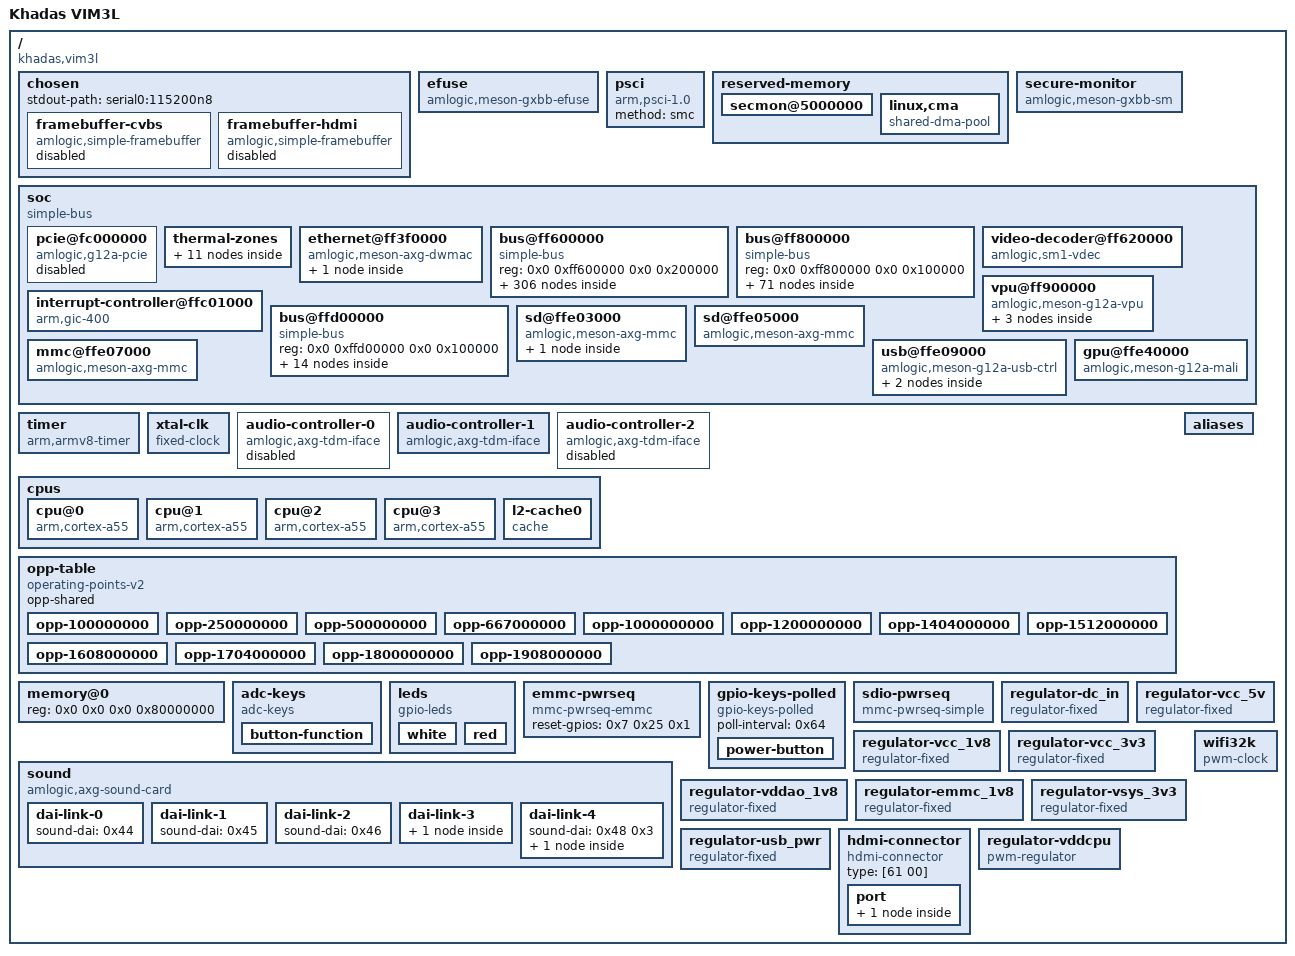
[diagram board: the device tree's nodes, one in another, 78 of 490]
/dts-v1/;

/ {
	interrupt-parent = <0x1>;
	#address-cells = <0x2>;
	#size-cells = <0x2>;
	compatible = "khadas,vim3l", "amlogic,sm1";
	model = "Khadas VIM3L";

	chosen {
		#address-cells = <0x2>;
		#size-cells = <0x2>;
		ranges;
		stdout-path = "serial0:115200n8";

		framebuffer-cvbs {
			compatible = "amlogic,simple-framebuffer", "simple-framebuffer";
			amlogic,pipeline = "vpu-cvbs";
			clocks = <0x2 0xa8 0x2 0x35 0x2 0x3a>;
			status = "disabled";
			power-domains = <0x3 0x0>;
		};

		framebuffer-hdmi {
			compatible = "amlogic,simple-framebuffer", "simple-framebuffer";
			amlogic,pipeline = "vpu-hdmi";
			clocks = <0x2 0xa8 0x2 0x35 0x2 0x3a>;
			status = "disabled";
			power-domains = <0x3 0x0>;
		};
	};

	efuse {
		compatible = "amlogic,meson-gxbb-efuse";
		clocks = <0x2 0x6a>;
		#address-cells = <0x1>;
		#size-cells = <0x1>;
		read-only;
		secure-monitor = <0x4>;
	};

	psci {
		compatible = "arm,psci-1.0";
		method = "smc";
	};

	reserved-memory {
		#address-cells = <0x2>;
		#size-cells = <0x2>;
		ranges;

		secmon@5000000 {
			reg = <0x0 0x5000000 0x0 0x300000>;
			no-map;
		};

		linux,cma {
			compatible = "shared-dma-pool";
			reusable;
			size = <0x0 0x38000000>;
			alignment = <0x0 0x400000>;
			linux,cma-default;
		};
	};

	secure-monitor {
		compatible = "amlogic,meson-gxbb-sm";
		phandle = <0x4>;
	};

	soc {
		compatible = "simple-bus";
		#address-cells = <0x2>;
		#size-cells = <0x2>;
		ranges;

		pcie@fc000000 {
			compatible = "amlogic,g12a-pcie", "snps,dw-pcie";
			reg = <0x0 0xfc000000 0x0 0x400000 0x0 0xff648000 0x0 0x2000 0x0 0xfc400000 0x0 0x200000>;
			reg-names = "elbi", "cfg", "config";
			interrupts = <0x0 0xdd 0x4>;
			#interrupt-cells = <0x1>;
			interrupt-map-mask = <0x0 0x0 0x0 0x0>;
			interrupt-map = <0x0 0x0 0x0 0x0 0x1 0x0 0xdf 0x4>;
			bus-range = <0x0 0xff>;
			#address-cells = <0x3>;
			#size-cells = <0x2>;
			device_type = "pci";
			ranges = <0x81000000 0x0 0x0 0x0 0xfc600000 0x0 0x100000 0x82000000 0x0 0xfc700000 0x0 0xfc700000 0x0 0x1900000>;
			clocks = <0x2 0x30 0x2 0x2d 0x2 0xc9>;
			clock-names = "general", "pclk", "port";
			resets = <0x5 0xc 0x5 0xf>;
			reset-names = "port", "apb";
			num-lanes = <0x1>;
			phys = <0x6 0x2>;
			phy-names = "pcie";
			status = "disabled";
			power-domains = <0x3 0x3>;
			reset-gpios = <0x7 0x39 0x1>;
		};

		thermal-zones {

			cpu-thermal {
				polling-delay = <0x3e8>;
				polling-delay-passive = <0x64>;
				thermal-sensors = <0x8>;

				trips {

					cpu-passive {
						temperature = <0x14c08>;
						hysteresis = <0x7d0>;
						type = "passive";
					};

					cpu-hot {
						temperature = <0x17318>;
						hysteresis = <0x7d0>;
						type = "hot";
					};

					cpu-critical {
						temperature = <0x1adb0>;
						hysteresis = <0x7d0>;
						type = "critical";
					};
				};
			};

			ddr-thermal {
				polling-delay = <0x3e8>;
				polling-delay-passive = <0x64>;
				thermal-sensors = <0x9>;

				trips {

					ddr-passive {
						temperature = <0x14c08>;
						hysteresis = <0x7d0>;
						type = "passive";
						phandle = <0xa>;
					};

					ddr-critical {
						temperature = <0x1adb0>;
						hysteresis = <0x7d0>;
						type = "critical";
					};
				};

				cooling-maps {

					map {
						trip = <0xa>;
						cooling-device = <0xb 0xffffffff 0xffffffff>;
					};
				};
			};
		};

		ethernet@ff3f0000 {
			compatible = "amlogic,meson-axg-dwmac", "snps,dwmac-3.70a", "snps,dwmac";
			reg = <0x0 0xff3f0000 0x0 0x10000 0x0 0xff634540 0x0 0x8>;
			interrupts = <0x0 0x8 0x4>;
			interrupt-names = "macirq";
			clocks = <0x2 0x26 0x2 0x2 0x2 0xd>;
			clock-names = "stmmaceth", "clkin0", "clkin1";
			rx-fifo-depth = <0x1000>;
			tx-fifo-depth = <0x800>;
			status = "okay";
			power-domains = <0x3 0x6>;
			pinctrl-0 = <0xc 0xd>;
			pinctrl-names = "default";
			phy-mode = "rgmii";
			phy-handle = <0xe>;
			amlogic,tx-delay-ns = <0x2>;

			mdio {
				#address-cells = <0x1>;
				#size-cells = <0x0>;
				compatible = "snps,dwmac-mdio";
				phandle = <0x1a>;
			};
		};

		bus@ff600000 {
			compatible = "simple-bus";
			reg = <0x0 0xff600000 0x0 0x200000>;
			#address-cells = <0x2>;
			#size-cells = <0x2>;
			ranges = <0x0 0x0 0x0 0xff600000 0x0 0x200000>;

			hdmi-tx@0 {
				compatible = "amlogic,meson-g12a-dw-hdmi";
				reg = <0x0 0x0 0x0 0x10000>;
				interrupts = <0x0 0x39 0x1>;
				resets = <0x5 0x13 0x5 0x42 0x5 0x4f>;
				reset-names = "hdmitx_apb", "hdmitx", "hdmitx_phy";
				clocks = <0x2 0xa8 0x2 0x35 0x2 0x3a>;
				clock-names = "isfr", "iahb", "venci";
				#address-cells = <0x1>;
				#size-cells = <0x0>;
				#sound-dai-cells = <0x0>;
				status = "okay";
				pinctrl-0 = <0xf 0x10>;
				pinctrl-names = "default";
				hdmi-supply = <0x11>;
				phandle = <0x21>;

				port@0 {
					reg = <0x0>;

					endpoint {
						remote-endpoint = <0x12>;
						phandle = <0x2b>;
					};
				};

				port@1 {
					reg = <0x1>;

					endpoint {
						remote-endpoint = <0x13>;
						phandle = <0x49>;
					};
				};
			};

			bus@30000 {
				compatible = "simple-bus";
				reg = <0x0 0x30000 0x0 0x2000>;
				#address-cells = <0x2>;
				#size-cells = <0x2>;
				ranges = <0x0 0x0 0x0 0x30000 0x0 0x2000>;

				rng@218 {
					compatible = "amlogic,meson-rng";
					reg = <0x0 0x218 0x0 0x4>;
				};
			};

			audio-controller@32000 {
				compatible = "amlogic,t9015";
				reg = <0x0 0x32000 0x0 0x14>;
				#sound-dai-cells = <0x0>;
				sound-name-prefix = "ACODEC";
				clocks = <0x2 0x24>;
				clock-names = "pclk";
				resets = <0x5 0x3d>;
				status = "disabled";
			};

			bus@34400 {
				compatible = "simple-bus";
				reg = <0x0 0x34400 0x0 0x400>;
				#address-cells = <0x2>;
				#size-cells = <0x2>;
				ranges = <0x0 0x0 0x0 0x34400 0x0 0x400>;

				pinctrl@40 {
					compatible = "amlogic,meson-g12a-periphs-pinctrl";
					#address-cells = <0x2>;
					#size-cells = <0x2>;
					ranges;
					phandle = <0x14>;

					bank@40 {
						reg = <0x0 0x40 0x0 0x4c 0x0 0xe8 0x0 0x18 0x0 0x120 0x0 0x18 0x0 0x2c0 0x0 0x40 0x0 0x340 0x0 0x1c>;
						reg-names = "gpio", "pull", "pull-enable", "mux", "ds";
						gpio-controller;
						#gpio-cells = <0x2>;
						gpio-ranges = <0x14 0x0 0x0 0x56>;
						phandle = <0x7>;
					};

					cec_ao_a_h {
						phandle = <0x20>;

						mux {
							groups = "cec_ao_a_h";
							function = "cec_ao_a_h";
							bias-disable;
						};
					};

					cec_ao_b_h {
						phandle = <0x22>;

						mux {
							groups = "cec_ao_b_h";
							function = "cec_ao_b_h";
							bias-disable;
						};
					};

					emmc {
						phandle = <0x36>;

						mux-0 {
							groups = "emmc_nand_d0", "emmc_nand_d1", "emmc_nand_d2", "emmc_nand_d3", "emmc_nand_d4", "emmc_nand_d5", "emmc_nand_d6", "emmc_nand_d7", "emmc_cmd";
							function = "emmc";
							bias-pull-up;
							drive-strength-microamp = <0xfa0>;
						};

						mux-1 {
							groups = "emmc_clk";
							function = "emmc";
							bias-disable;
							drive-strength-microamp = <0xfa0>;
						};
					};

					emmc-ds {
						phandle = <0x37>;

						mux {
							groups = "emmc_nand_ds";
							function = "emmc";
							bias-pull-down;
							drive-strength-microamp = <0xfa0>;
						};
					};

					emmc_clk_gate {
						phandle = <0x38>;

						mux {
							groups = "BOOT_8";
							function = "gpio_periphs";
							bias-pull-down;
							drive-strength-microamp = <0xfa0>;
						};
					};

					hdmitx_ddc {
						phandle = <0x10>;

						mux {
							groups = "hdmitx_sda", "hdmitx_sck";
							function = "hdmitx";
							bias-disable;
							drive-strength-microamp = <0xfa0>;
						};
					};

					hdmitx_hpd {
						phandle = <0xf>;

						mux {
							groups = "hdmitx_hpd_in";
							function = "hdmitx";
							bias-disable;
						};
					};

					i2c0-sda-c {

						mux {
							groups = "i2c0_sda_c";
							function = "i2c0";
							bias-disable;
							drive-strength-microamp = <0xbb8>;
						};
					};

					i2c0-sck-c {

						mux {
							groups = "i2c0_sck_c";
							function = "i2c0";
							bias-disable;
							drive-strength-microamp = <0xbb8>;
						};
					};

					i2c0-sda-z0 {

						mux {
							groups = "i2c0_sda_z0";
							function = "i2c0";
							bias-disable;
							drive-strength-microamp = <0xbb8>;
						};
					};

					i2c0-sck-z1 {

						mux {
							groups = "i2c0_sck_z1";
							function = "i2c0";
							bias-disable;
							drive-strength-microamp = <0xbb8>;
						};
					};

					i2c0-sda-z7 {

						mux {
							groups = "i2c0_sda_z7";
							function = "i2c0";
							bias-disable;
							drive-strength-microamp = <0xbb8>;
						};
					};

					i2c0-sda-z8 {

						mux {
							groups = "i2c0_sda_z8";
							function = "i2c0";
							bias-disable;
							drive-strength-microamp = <0xbb8>;
						};
					};

					i2c1-sda-x {

						mux {
							groups = "i2c1_sda_x";
							function = "i2c1";
							bias-disable;
							drive-strength-microamp = <0xbb8>;
						};
					};

					i2c1-sck-x {

						mux {
							groups = "i2c1_sck_x";
							function = "i2c1";
							bias-disable;
							drive-strength-microamp = <0xbb8>;
						};
					};

					i2c1-sda-h2 {

						mux {
							groups = "i2c1_sda_h2";
							function = "i2c1";
							bias-disable;
							drive-strength-microamp = <0xbb8>;
						};
					};

					i2c1-sck-h3 {

						mux {
							groups = "i2c1_sck_h3";
							function = "i2c1";
							bias-disable;
							drive-strength-microamp = <0xbb8>;
						};
					};

					i2c1-sda-h6 {

						mux {
							groups = "i2c1_sda_h6";
							function = "i2c1";
							bias-disable;
							drive-strength-microamp = <0xbb8>;
						};
					};

					i2c1-sck-h7 {

						mux {
							groups = "i2c1_sck_h7";
							function = "i2c1";
							bias-disable;
							drive-strength-microamp = <0xbb8>;
						};
					};

					i2c2-sda-x {

						mux {
							groups = "i2c2_sda_x";
							function = "i2c2";
							bias-disable;
							drive-strength-microamp = <0xbb8>;
						};
					};

					i2c2-sck-x {

						mux {
							groups = "i2c2_sck_x";
							function = "i2c2";
							bias-disable;
							drive-strength-microamp = <0xbb8>;
						};
					};

					i2c2-sda-z {

						mux {
							groups = "i2c2_sda_z";
							function = "i2c2";
							bias-disable;
							drive-strength-microamp = <0xbb8>;
						};
					};

					i2c2-sck-z {

						mux {
							groups = "i2c2_sck_z";
							function = "i2c2";
							bias-disable;
							drive-strength-microamp = <0xbb8>;
						};
					};

					i2c3-sda-h {

						mux {
							groups = "i2c3_sda_h";
							function = "i2c3";
							bias-disable;
							drive-strength-microamp = <0xbb8>;
						};
					};

					i2c3-sck-h {

						mux {
							groups = "i2c3_sck_h";
							function = "i2c3";
							bias-disable;
							drive-strength-microamp = <0xbb8>;
						};
					};

					i2c3-sda-a {

						mux {
							groups = "i2c3_sda_a";
							function = "i2c3";
							bias-disable;
							drive-strength-microamp = <0xbb8>;
						};
					};

					i2c3-sck-a {

						mux {
							groups = "i2c3_sck_a";
							function = "i2c3";
							bias-disable;
							drive-strength-microamp = <0xbb8>;
						};
					};

					mclk0-a {

						mux {
							groups = "mclk0_a";
							function = "mclk0";
							bias-disable;
							drive-strength-microamp = <0xbb8>;
						};
					};

					mclk1-a {

						mux {
							groups = "mclk1_a";
							function = "mclk1";
							bias-disable;
							drive-strength-microamp = <0xbb8>;
						};
					};

					mclk1-x {

						mux {
							groups = "mclk1_x";
							function = "mclk1";
							bias-disable;
							drive-strength-microamp = <0xbb8>;
						};
					};

					mclk1-z {

						mux {
							groups = "mclk1_z";
							function = "mclk1";
							bias-disable;
							drive-strength-microamp = <0xbb8>;
						};
					};

					pdm-din0-a {

						mux {
							groups = "pdm_din0_a";
							function = "pdm";
							bias-disable;
						};
					};

					pdm-din0-c {

						mux {
							groups = "pdm_din0_c";
							function = "pdm";
							bias-disable;
						};
					};

					pdm-din0-x {

						mux {
							groups = "pdm_din0_x";
							function = "pdm";
							bias-disable;
						};
					};

					pdm-din0-z {

						mux {
							groups = "pdm_din0_z";
							function = "pdm";
							bias-disable;
						};
					};

					pdm-din1-a {

						mux {
							groups = "pdm_din1_a";
							function = "pdm";
							bias-disable;
						};
					};

					pdm-din1-c {

						mux {
							groups = "pdm_din1_c";
							function = "pdm";
							bias-disable;
						};
					};

					pdm-din1-x {

						mux {
							groups = "pdm_din1_x";
							function = "pdm";
							bias-disable;
						};
					};

					pdm-din1-z {

						mux {
							groups = "pdm_din1_z";
							function = "pdm";
							bias-disable;
						};
					};

					pdm-din2-a {

						mux {
							groups = "pdm_din2_a";
							function = "pdm";
							bias-disable;
						};
					};

					pdm-din2-c {

						mux {
							groups = "pdm_din2_c";
							function = "pdm";
							bias-disable;
						};
					};

					pdm-din2-x {

						mux {
							groups = "pdm_din2_x";
							function = "pdm";
							bias-disable;
						};
					};

					pdm-din2-z {

						mux {
							groups = "pdm_din2_z";
							function = "pdm";
							bias-disable;
						};
					};

					pdm-din3-a {

						mux {
							groups = "pdm_din3_a";
							function = "pdm";
							bias-disable;
						};
					};

					pdm-din3-c {

						mux {
							groups = "pdm_din3_c";
							function = "pdm";
							bias-disable;
						};
					};

					pdm-din3-x {

						mux {
							groups = "pdm_din3_x";
							function = "pdm";
							bias-disable;
						};
					};

					pdm-din3-z {

						mux {
							groups = "pdm_din3_z";
							function = "pdm";
							bias-disable;
						};
					};

					pdm-dclk-a {

						mux {
							groups = "pdm_dclk_a";
							function = "pdm";
							bias-disable;
							drive-strength-microamp = <0x1f4>;
						};
					};

					pdm-dclk-c {

						mux {
							groups = "pdm_dclk_c";
							function = "pdm";
							bias-disable;
							drive-strength-microamp = <0x1f4>;
						};
					};

					pdm-dclk-x {

						mux {
							groups = "pdm_dclk_x";
							function = "pdm";
							bias-disable;
							drive-strength-microamp = <0x1f4>;
						};
					};

					pdm-dclk-z {

						mux {
							groups = "pdm_dclk_z";
							function = "pdm";
							bias-disable;
							drive-strength-microamp = <0x1f4>;
						};
					};

					pwm-a {

						mux {
							groups = "pwm_a";
							function = "pwm_a";
							bias-disable;
						};
					};

					pwm-b-x7 {

						mux {
							groups = "pwm_b_x7";
							function = "pwm_b";
							bias-disable;
						};
					};

					pwm-b-x19 {

						mux {
							groups = "pwm_b_x19";
							function = "pwm_b";
							bias-disable;
						};
					};

					pwm-c-c {

						mux {
							groups = "pwm_c_c";
							function = "pwm_c";
							bias-disable;
						};
					};

					pwm-c-x5 {

						mux {
							groups = "pwm_c_x5";
							function = "pwm_c";
							bias-disable;
						};
					};

					pwm-c-x8 {

						mux {
							groups = "pwm_c_x8";
							function = "pwm_c";
							bias-disable;
						};
					};

					pwm-d-x3 {

						mux {
							groups = "pwm_d_x3";
							function = "pwm_d";
							bias-disable;
						};
					};

					pwm-d-x6 {

						mux {
							groups = "pwm_d_x6";
							function = "pwm_d";
							bias-disable;
						};
					};

					pwm-e {
						phandle = <0x2c>;

						mux {
							groups = "pwm_e";
							function = "pwm_e";
							bias-disable;
						};
					};

					pwm-f-x {

						mux {
							groups = "pwm_f_x";
							function = "pwm_f";
							bias-disable;
						};
					};

					pwm-f-h {

						mux {
							groups = "pwm_f_h";
							function = "pwm_f";
							bias-disable;
						};
					};

					sdcard_c {
						phandle = <0x34>;

						mux-0 {
							groups = "sdcard_d0_c", "sdcard_d1_c", "sdcard_d2_c", "sdcard_d3_c", "sdcard_cmd_c";
							function = "sdcard";
							bias-pull-up;
							drive-strength-microamp = <0xfa0>;
						};

						mux-1 {
							groups = "sdcard_clk_c";
							function = "sdcard";
							bias-disable;
							drive-strength-microamp = <0xfa0>;
						};
					};

					sdcard_clk_gate_c {
						phandle = <0x35>;

						mux {
							groups = "GPIOC_4";
							function = "gpio_periphs";
							bias-pull-down;
							drive-strength-microamp = <0xfa0>;
						};
					};

					sdcard_z {

						mux-0 {
							groups = "sdcard_d0_z", "sdcard_d1_z", "sdcard_d2_z", "sdcard_d3_z", "sdcard_cmd_z";
							function = "sdcard";
							bias-pull-up;
							drive-strength-microamp = <0xfa0>;
						};

						mux-1 {
							groups = "sdcard_clk_z";
							function = "sdcard";
							bias-disable;
							drive-strength-microamp = <0xfa0>;
						};
					};

					sdcard_clk_gate_z {

						mux {
							groups = "GPIOZ_6";
							function = "gpio_periphs";
							bias-pull-down;
							drive-strength-microamp = <0xfa0>;
						};
					};

					sdio {
						phandle = <0x30>;

						mux {
							groups = "sdio_d0", "sdio_d1", "sdio_d2", "sdio_d3", "sdio_clk", "sdio_cmd";
							function = "sdio";
							bias-disable;
							drive-strength-microamp = <0xfa0>;
						};
					};

					sdio_clk_gate {
						phandle = <0x31>;

						mux {
							groups = "GPIOX_4";
							function = "gpio_periphs";
							bias-pull-down;
							drive-strength-microamp = <0xfa0>;
						};
					};

					spdif-in-a10 {

						mux {
							groups = "spdif_in_a10";
							function = "spdif_in";
							bias-disable;
						};
					};

					spdif-in-a12 {

						mux {
							groups = "spdif_in_a12";
							function = "spdif_in";
							bias-disable;
						};
					};

					spdif-in-h {

						mux {
							groups = "spdif_in_h";
							function = "spdif_in";
							bias-disable;
						};
					};

					spdif-out-h {

						mux {
							groups = "spdif_out_h";
							function = "spdif_out";
							drive-strength-microamp = <0x1f4>;
							bias-disable;
						};
					};

					spdif-out-a11 {

						mux {
							groups = "spdif_out_a11";
							function = "spdif_out";
							drive-strength-microamp = <0x1f4>;
							bias-disable;
						};
					};

					spdif-out-a13 {

						mux {
							groups = "spdif_out_a13";
							function = "spdif_out";
							drive-strength-microamp = <0x1f4>;
							bias-disable;
						};
					};

					tdm-a-din0 {

						mux {
							groups = "tdm_a_din0";
							function = "tdm_a";
							bias-disable;
						};
					};

					tdm-a-din1 {

						mux {
							groups = "tdm_a_din1";
							function = "tdm_a";
							bias-disable;
						};
					};

					tdm-a-dout0 {

						mux {
							groups = "tdm_a_dout0";
							function = "tdm_a";
							bias-disable;
							drive-strength-microamp = <0xbb8>;
						};
					};

					tdm-a-dout1 {

						mux {
							groups = "tdm_a_dout1";
							function = "tdm_a";
							bias-disable;
							drive-strength-microamp = <0xbb8>;
						};
					};

					tdm-a-fs {

						mux {
							groups = "tdm_a_fs";
							function = "tdm_a";
							bias-disable;
							drive-strength-microamp = <0xbb8>;
						};
					};

					tdm-a-sclk {

						mux {
							groups = "tdm_a_sclk";
							function = "tdm_a";
							bias-disable;
							drive-strength-microamp = <0xbb8>;
						};
					};

					tdm-a-slv-fs {

						mux {
							groups = "tdm_a_slv_fs";
							function = "tdm_a";
							bias-disable;
						};
					};

					tdm-a-slv-sclk {

						mux {
							groups = "tdm_a_slv_sclk";
							function = "tdm_a";
							bias-disable;
						};
					};

					tdm-b-din0 {

						mux {
							groups = "tdm_b_din0";
							function = "tdm_b";
							bias-disable;
						};
					};

					tdm-b-din1 {

						mux {
							groups = "tdm_b_din1";
							function = "tdm_b";
							bias-disable;
						};
					};

					tdm-b-din2 {

						mux {
							groups = "tdm_b_din2";
							function = "tdm_b";
							bias-disable;
						};
					};

					tdm-b-din3-a {

						mux {
							groups = "tdm_b_din3_a";
							function = "tdm_b";
							bias-disable;
						};
					};

					tdm-b-din3-h {

						mux {
							groups = "tdm_b_din3_h";
							function = "tdm_b";
							bias-disable;
						};
					};

					tdm-b-dout0 {

						mux {
							groups = "tdm_b_dout0";
							function = "tdm_b";
							bias-disable;
							drive-strength-microamp = <0xbb8>;
						};
					};

					tdm-b-dout1 {

						mux {
							groups = "tdm_b_dout1";
							function = "tdm_b";
							bias-disable;
							drive-strength-microamp = <0xbb8>;
						};
					};

					tdm-b-dout2 {

						mux {
							groups = "tdm_b_dout2";
							function = "tdm_b";
							bias-disable;
							drive-strength-microamp = <0xbb8>;
						};
					};

					tdm-b-dout3-a {

						mux {
							groups = "tdm_b_dout3_a";
							function = "tdm_b";
							bias-disable;
							drive-strength-microamp = <0xbb8>;
						};
					};

					tdm-b-dout3-h {

						mux {
							groups = "tdm_b_dout3_h";
							function = "tdm_b";
							bias-disable;
							drive-strength-microamp = <0xbb8>;
						};
					};

					tdm-b-fs {

						mux {
							groups = "tdm_b_fs";
							function = "tdm_b";
							bias-disable;
							drive-strength-microamp = <0xbb8>;
						};
					};

					tdm-b-sclk {

						mux {
							groups = "tdm_b_sclk";
							function = "tdm_b";
							bias-disable;
							drive-strength-microamp = <0xbb8>;
						};
					};

					tdm-b-slv-fs {

						mux {
							groups = "tdm_b_slv_fs";
							function = "tdm_b";
							bias-disable;
						};
					};

					tdm-b-slv-sclk {

						mux {
							groups = "tdm_b_slv_sclk";
							function = "tdm_b";
							bias-disable;
						};
					};

					tdm-c-din0-a {

						mux {
							groups = "tdm_c_din0_a";
							function = "tdm_c";
							bias-disable;
						};
					};

					tdm-c-din0-z {

						mux {
							groups = "tdm_c_din0_z";
							function = "tdm_c";
							bias-disable;
						};
					};

					tdm-c-din1-a {

						mux {
							groups = "tdm_c_din1_a";
							function = "tdm_c";
							bias-disable;
						};
					};

					tdm-c-din1-z {

						mux {
							groups = "tdm_c_din1_z";
							function = "tdm_c";
							bias-disable;
						};
					};

					tdm-c-din2-a {

						mux {
							groups = "tdm_c_din2_a";
							function = "tdm_c";
							bias-disable;
						};
					};

					eth-leds {

						mux {
							groups = "eth_link_led", "eth_act_led";
							function = "eth";
							bias-disable;
						};
					};

					eth {
						phandle = <0xc>;

						mux {
							groups = "eth_mdio", "eth_mdc", "eth_rgmii_rx_clk", "eth_rx_dv", "eth_rxd0", "eth_rxd1", "eth_txen", "eth_txd0", "eth_txd1";
							function = "eth";
							drive-strength-microamp = <0xfa0>;
							bias-disable;
						};
					};

					eth-rgmii {
						phandle = <0xd>;

						mux {
							groups = "eth_rxd2_rgmii", "eth_rxd3_rgmii", "eth_rgmii_tx_clk", "eth_txd2_rgmii", "eth_txd3_rgmii";
							function = "eth";
							drive-strength-microamp = <0xfa0>;
							bias-disable;
						};
					};

					tdm-c-din2-z {

						mux {
							groups = "tdm_c_din2_z";
							function = "tdm_c";
							bias-disable;
						};
					};

					tdm-c-din3-a {

						mux {
							groups = "tdm_c_din3_a";
							function = "tdm_c";
							bias-disable;
						};
					};

					tdm-c-din3-z {

						mux {
							groups = "tdm_c_din3_z";
							function = "tdm_c";
							bias-disable;
						};
					};

					tdm-c-dout0-a {

						mux {
							groups = "tdm_c_dout0_a";
							function = "tdm_c";
							bias-disable;
							drive-strength-microamp = <0xbb8>;
						};
					};

					tdm-c-dout0-z {

						mux {
							groups = "tdm_c_dout0_z";
							function = "tdm_c";
							bias-disable;
							drive-strength-microamp = <0xbb8>;
						};
					};

					tdm-c-dout1-a {

						mux {
							groups = "tdm_c_dout1_a";
							function = "tdm_c";
							bias-disable;
							drive-strength-microamp = <0xbb8>;
						};
					};

					tdm-c-dout1-z {

						mux {
							groups = "tdm_c_dout1_z";
							function = "tdm_c";
							bias-disable;
							drive-strength-microamp = <0xbb8>;
						};
					};

					tdm-c-dout2-a {

						mux {
							groups = "tdm_c_dout2_a";
							function = "tdm_c";
							bias-disable;
							drive-strength-microamp = <0xbb8>;
						};
					};

					tdm-c-dout2-z {

						mux {
							groups = "tdm_c_dout2_z";
							function = "tdm_c";
							bias-disable;
							drive-strength-microamp = <0xbb8>;
						};
					};

					tdm-c-dout3-a {

						mux {
							groups = "tdm_c_dout3_a";
							function = "tdm_c";
							bias-disable;
							drive-strength-microamp = <0xbb8>;
						};
					};

					tdm-c-dout3-z {

						mux {
							groups = "tdm_c_dout3_z";
							function = "tdm_c";
							bias-disable;
							drive-strength-microamp = <0xbb8>;
						};
					};

					tdm-c-fs-a {

						mux {
							groups = "tdm_c_fs_a";
							function = "tdm_c";
							bias-disable;
							drive-strength-microamp = <0xbb8>;
						};
					};

					tdm-c-fs-z {

						mux {
							groups = "tdm_c_fs_z";
							function = "tdm_c";
							bias-disable;
							drive-strength-microamp = <0xbb8>;
						};
					};

					tdm-c-sclk-a {

						mux {
							groups = "tdm_c_sclk_a";
							function = "tdm_c";
							bias-disable;
							drive-strength-microamp = <0xbb8>;
						};
					};

					tdm-c-sclk-z {

						mux {
							groups = "tdm_c_sclk_z";
							function = "tdm_c";
							bias-disable;
							drive-strength-microamp = <0xbb8>;
						};
					};

					tdm-c-slv-fs-a {

						mux {
							groups = "tdm_c_slv_fs_a";
							function = "tdm_c";
							bias-disable;
						};
					};

					tdm-c-slv-fs-z {

						mux {
							groups = "tdm_c_slv_fs_z";
							function = "tdm_c";
							bias-disable;
						};
					};

					tdm-c-slv-sclk-a {

						mux {
							groups = "tdm_c_slv_sclk_a";
							function = "tdm_c";
							bias-disable;
						};
					};

					tdm-c-slv-sclk-z {

						mux {
							groups = "tdm_c_slv_sclk_z";
							function = "tdm_c";
							bias-disable;
						};
					};

					uart-a {
						phandle = <0x2d>;

						mux {
							groups = "uart_a_tx", "uart_a_rx";
							function = "uart_a";
							bias-disable;
						};
					};

					uart-a-cts-rts {
						phandle = <0x2e>;

						mux {
							groups = "uart_a_cts", "uart_a_rts";
							function = "uart_a";
							bias-disable;
						};
					};

					uart-b {

						mux {
							groups = "uart_b_tx", "uart_b_rx";
							function = "uart_b";
							bias-disable;
						};
					};

					uart-c {

						mux {
							groups = "uart_c_tx", "uart_c_rx";
							function = "uart_c";
							bias-disable;
						};
					};

					uart-c-cts-rts {

						mux {
							groups = "uart_c_cts", "uart_c_rts";
							function = "uart_c";
							bias-disable;
						};
					};
				};
			};

			temperature-sensor@34800 {
				compatible = "amlogic,g12a-cpu-thermal", "amlogic,g12a-thermal";
				reg = <0x0 0x34800 0x0 0x50>;
				interrupts = <0x0 0x23 0x1>;
				clocks = <0x2 0xd4>;
				#thermal-sensor-cells = <0x0>;
				amlogic,ao-secure = <0x15>;
				phandle = <0x8>;
			};

			temperature-sensor@34c00 {
				compatible = "amlogic,g12a-ddr-thermal", "amlogic,g12a-thermal";
				reg = <0x0 0x34c00 0x0 0x50>;
				interrupts = <0x0 0x24 0x1>;
				clocks = <0x2 0xd4>;
				#thermal-sensor-cells = <0x0>;
				amlogic,ao-secure = <0x15>;
				phandle = <0x9>;
			};

			phy@36000 {
				compatible = "amlogic,g12a-usb2-phy";
				reg = <0x0 0x36000 0x0 0x2000>;
				clocks = <0x16>;
				clock-names = "xtal";
				resets = <0x5 0x30>;
				reset-names = "phy";
				#phy-cells = <0x0>;
				phy-supply = <0x17>;
				phandle = <0x3b>;
			};

			bus@38000 {
				compatible = "simple-bus";
				reg = <0x0 0x38000 0x0 0x400>;
				#address-cells = <0x2>;
				#size-cells = <0x2>;
				ranges = <0x0 0x0 0x0 0x38000 0x0 0x400>;

				video-lut@48 {
					compatible = "amlogic,canvas";
					reg = <0x0 0x48 0x0 0x14>;
					phandle = <0x2a>;
				};
			};

			phy@3a000 {
				compatible = "amlogic,g12a-usb2-phy";
				reg = <0x0 0x3a000 0x0 0x2000>;
				clocks = <0x16>;
				clock-names = "xtal";
				resets = <0x5 0x31>;
				reset-names = "phy";
				#phy-cells = <0x0>;
				phy-supply = <0x18>;
				phandle = <0x3c>;
			};

			bus@3c000 {
				compatible = "simple-bus";
				reg = <0x0 0x3c000 0x0 0x1400>;
				#address-cells = <0x2>;
				#size-cells = <0x2>;
				ranges = <0x0 0x0 0x0 0x3c000 0x0 0x1400>;

				system-controller@0 {
					compatible = "amlogic,meson-gx-hhi-sysctrl", "simple-mfd", "syscon";
					reg = <0x0 0x0 0x0 0x400>;

					clock-controller {
						compatible = "amlogic,sm1-clkc";
						#clock-cells = <0x1>;
						clocks = <0x16>;
						clock-names = "xtal";
						phandle = <0x2>;
					};

					power-controller {
						compatible = "amlogic,meson-sm1-pwrc";
						#power-domain-cells = <0x1>;
						amlogic,ao-sysctrl = <0x19>;
						resets = <0x5 0x5 0x5 0xa 0x5 0xd 0x5 0x25 0x5 0x85 0x5 0x86 0x5 0x87 0x5 0x89 0x5 0x8c 0x5 0x8d 0x5 0xe7>;
						reset-names = "viu", "venc", "vcbus", "bt656", "rdma", "venci", "vencp", "vdac", "vdi6", "vencl", "vid_lock";
						clocks = <0x2 0x74 0x2 0x7c>;
						clock-names = "vpu", "vapb";
						assigned-clocks = <0x2 0x6e 0x2 0x70 0x2 0x74 0x2 0x75 0x2 0x77 0x2 0x7b>;
						assigned-clock-parents = <0x2 0x3 0x0 0x2 0x70 0x2 0x4 0x0 0x2 0x77>;
						assigned-clock-rates = <0x0 0x27bc86aa 0x0 0x0 0xee6b280 0x0>;
						phandle = <0x3>;
					};
				};
			};

			phy@46000 {
				compatible = "amlogic,g12a-usb3-pcie-phy";
				reg = <0x0 0x46000 0x0 0x2000>;
				clocks = <0x2 0xc9>;
				clock-names = "ref_clk";
				resets = <0x5 0xe>;
				reset-names = "phy";
				assigned-clocks = <0x2 0xc9>;
				assigned-clock-rates = <0x5f5e100>;
				#phy-cells = <0x1>;
				phy-supply = <0x18>;
				phandle = <0x6>;
			};

			mdio-multiplexer@4c000 {
				compatible = "amlogic,g12a-mdio-mux";
				reg = <0x0 0x4c000 0x0 0xa4>;
				clocks = <0x2 0x13 0x16 0x2 0xb1>;
				clock-names = "pclk", "clkin0", "clkin1";
				mdio-parent-bus = <0x1a>;
				#address-cells = <0x1>;
				#size-cells = <0x0>;

				mdio@0 {
					reg = <0x0>;
					#address-cells = <0x1>;
					#size-cells = <0x0>;

					ethernet-phy@0 {
						reg = <0x0>;
						max-speed = <0x3e8>;
						interrupt-parent = <0x1b>;
						interrupts = <0x1a 0x8>;
						phandle = <0xe>;
					};
				};

				mdio@1 {
					reg = <0x1>;
					#address-cells = <0x1>;
					#size-cells = <0x0>;

					ethernet_phy@8 {
						compatible = "ethernet-phy-id0180.3301", "ethernet-phy-ieee802.3-c22";
						interrupts = <0x0 0x9 0x4>;
						reg = <0x8>;
						max-speed = <0x64>;
					};
				};
			};

			bus@60000 {
				compatible = "simple-bus";
				reg = <0x0 0x60000 0x0 0x1000>;
				#address-cells = <0x2>;
				#size-cells = <0x2>;
				ranges = <0x0 0x0 0x0 0x60000 0x0 0x1000>;

				clock-controller@0 {
					status = "okay";
					compatible = "amlogic,sm1-audio-clkc";
					reg = <0x0 0x0 0x0 0xb4>;
					#clock-cells = <0x1>;
					#reset-cells = <0x1>;
					clocks = <0x2 0x25 0x2 0xb 0x2 0xc 0x2 0xd 0x2 0xe 0x2 0x4a 0x2 0x3 0x2 0x4 0x2 0x5>;
					clock-names = "pclk", "mst_in0", "mst_in1", "mst_in2", "mst_in3", "mst_in4", "mst_in5", "mst_in6", "mst_in7";
					resets = <0x5 0x41>;
					phandle = <0x1c>;
				};

				audio-controller@100 {
					compatible = "amlogic,sm1-toddr", "amlogic,axg-toddr";
					reg = <0x0 0x100 0x0 0x2c>;
					#sound-dai-cells = <0x0>;
					sound-name-prefix = "TODDR_A";
					interrupts = <0x0 0x94 0x1>;
					clocks = <0x1c 0x29>;
					resets = <0x1d 0x0 0x1c 0x6>;
					reset-names = "arb", "rst";
					amlogic,fifo-depth = <0x2000>;
					status = "disabled";
				};

				audio-controller@140 {
					compatible = "amlogic,sm1-toddr", "amlogic,axg-toddr";
					reg = <0x0 0x140 0x0 0x2c>;
					#sound-dai-cells = <0x0>;
					sound-name-prefix = "TODDR_B";
					interrupts = <0x0 0x95 0x1>;
					clocks = <0x1c 0x2a>;
					resets = <0x1d 0x1 0x1c 0x7>;
					reset-names = "arb", "rst";
					amlogic,fifo-depth = <0x100>;
					status = "disabled";
				};

				audio-controller@180 {
					compatible = "amlogic,sm1-toddr", "amlogic,axg-toddr";
					reg = <0x0 0x180 0x0 0x2c>;
					#sound-dai-cells = <0x0>;
					sound-name-prefix = "TODDR_C";
					interrupts = <0x0 0x96 0x1>;
					clocks = <0x1c 0x2b>;
					resets = <0x1d 0x2 0x1c 0x8>;
					reset-names = "arb", "rst";
					amlogic,fifo-depth = <0x100>;
					status = "disabled";
				};

				audio-controller@1c0 {
					compatible = "amlogic,sm1-frddr", "amlogic,axg-frddr";
					reg = <0x0 0x1c0 0x0 0x2c>;
					#sound-dai-cells = <0x0>;
					sound-name-prefix = "FRDDR_A";
					interrupts = <0x0 0x98 0x1>;
					clocks = <0x1c 0x26>;
					resets = <0x1d 0x3 0x1c 0x9>;
					reset-names = "arb", "rst";
					amlogic,fifo-depth = <0x200>;
					status = "okay";
					phandle = <0x44>;
				};

				audio-controller@200 {
					compatible = "amlogic,sm1-frddr", "amlogic,axg-frddr";
					reg = <0x0 0x200 0x0 0x2c>;
					#sound-dai-cells = <0x0>;
					sound-name-prefix = "FRDDR_B";
					interrupts = <0x0 0x99 0x1>;
					clocks = <0x1c 0x27>;
					resets = <0x1d 0x4 0x1c 0xa>;
					reset-names = "arb", "rst";
					amlogic,fifo-depth = <0x100>;
					status = "okay";
					phandle = <0x45>;
				};

				audio-controller@240 {
					compatible = "amlogic,sm1-frddr", "amlogic,axg-frddr";
					reg = <0x0 0x240 0x0 0x2c>;
					#sound-dai-cells = <0x0>;
					sound-name-prefix = "FRDDR_C";
					interrupts = <0x0 0x9a 0x1>;
					clocks = <0x1c 0x28>;
					resets = <0x1d 0x5 0x1c 0xb>;
					reset-names = "arb", "rst";
					amlogic,fifo-depth = <0x100>;
					status = "okay";
					phandle = <0x46>;
				};

				reset-controller@280 {
					status = "okay";
					compatible = "amlogic,meson-sm1-audio-arb";
					reg = <0x0 0x280 0x0 0x4>;
					#reset-cells = <0x1>;
					clocks = <0x1c 0x1d>;
					phandle = <0x1d>;
				};

				audio-controller@300 {
					compatible = "amlogic,sm1-tdmin", "amlogic,axg-tdmin";
					reg = <0x0 0x300 0x0 0x40>;
					sound-name-prefix = "TDMIN_A";
					resets = <0x1c 0x1>;
					clocks = <0x1c 0x1f 0x1c 0x7b 0x1c 0x74 0x1c 0x82 0x1c 0x82>;
					clock-names = "pclk", "sclk", "sclk_sel", "lrclk", "lrclk_sel";
					status = "disabled";
				};

				audio-controller@340 {
					compatible = "amlogic,sm1-tdmin", "amlogic,axg-tdmin";
					reg = <0x0 0x340 0x0 0x40>;
					sound-name-prefix = "TDMIN_B";
					resets = <0x1c 0x2>;
					clocks = <0x1c 0x20 0x1c 0x7c 0x1c 0x75 0x1c 0x83 0x1c 0x83>;
					clock-names = "pclk", "sclk", "sclk_sel", "lrclk", "lrclk_sel";
					status = "disabled";
				};

				audio-controller@380 {
					compatible = "amlogic,sm1-tdmin", "amlogic,axg-tdmin";
					reg = <0x0 0x380 0x0 0x40>;
					sound-name-prefix = "TDMIN_C";
					resets = <0x1c 0x3>;
					clocks = <0x1c 0x21 0x1c 0x7d 0x1c 0x76 0x1c 0x84 0x1c 0x84>;
					clock-names = "pclk", "sclk", "sclk_sel", "lrclk", "lrclk_sel";
					status = "disabled";
				};

				audio-controller@3c0 {
					compatible = "amlogic,sm1-tdmin", "amlogic,axg-tdmin";
					reg = <0x0 0x3c0 0x0 0x40>;
					sound-name-prefix = "TDMIN_LB";
					resets = <0x1c 0x4>;
					clocks = <0x1c 0x22 0x1c 0x7e 0x1c 0x77 0x1c 0x85 0x1c 0x85>;
					clock-names = "pclk", "sclk", "sclk_sel", "lrclk", "lrclk_sel";
					status = "disabled";
				};

				audio-controller@500 {
					compatible = "amlogic,sm1-tdmout";
					reg = <0x0 0x500 0x0 0x40>;
					sound-name-prefix = "TDMOUT_A";
					resets = <0x1c 0xc>;
					clocks = <0x1c 0x23 0x1c 0x7f 0x1c 0x78 0x1c 0x86 0x1c 0x86>;
					clock-names = "pclk", "sclk", "sclk_sel", "lrclk", "lrclk_sel";
					status = "disabled";
				};

				audio-controller@540 {
					compatible = "amlogic,sm1-tdmout";
					reg = <0x0 0x540 0x0 0x40>;
					sound-name-prefix = "TDMOUT_B";
					resets = <0x1c 0xd>;
					clocks = <0x1c 0x24 0x1c 0x80 0x1c 0x79 0x1c 0x87 0x1c 0x87>;
					clock-names = "pclk", "sclk", "sclk_sel", "lrclk", "lrclk_sel";
					status = "okay";
					phandle = <0x43>;
				};

				audio-controller@580 {
					compatible = "amlogic,sm1-tdmout";
					reg = <0x0 0x580 0x0 0x40>;
					sound-name-prefix = "TDMOUT_C";
					resets = <0x1c 0xe>;
					clocks = <0x1c 0x25 0x1c 0x81 0x1c 0x7a 0x1c 0x88 0x1c 0x88>;
					clock-names = "pclk", "sclk", "sclk_sel", "lrclk", "lrclk_sel";
					status = "disabled";
				};

				audio-controller@744 {
					compatible = "amlogic,sm1-tohdmitx", "amlogic,g12a-tohdmitx";
					reg = <0x0 0x744 0x0 0x4>;
					#sound-dai-cells = <0x1>;
					sound-name-prefix = "TOHDMITX";
					resets = <0x1c 0x18>;
					status = "okay";
					phandle = <0x48>;
				};

				audio-controller@840 {
					compatible = "amlogic,sm1-toddr", "amlogic,axg-toddr";
					reg = <0x0 0x840 0x0 0x2c>;
					#sound-dai-cells = <0x0>;
					sound-name-prefix = "TODDR_D";
					interrupts = <0x0 0x31 0x1>;
					clocks = <0x1c 0xab>;
					resets = <0x1d 0x6 0x1c 0x21>;
					reset-names = "arb", "rst";
					amlogic,fifo-depth = <0x100>;
					status = "disabled";
				};

				audio-controller@880 {
					compatible = "amlogic,sm1-frddr", "amlogic,axg-frddr";
					reg = <0x0 0x880 0x0 0x2c>;
					#sound-dai-cells = <0x0>;
					sound-name-prefix = "FRDDR_D";
					interrupts = <0x0 0x32 0x1>;
					clocks = <0x1c 0xaa>;
					resets = <0x1d 0x7 0x1c 0x20>;
					reset-names = "arb", "rst";
					amlogic,fifo-depth = <0x100>;
					status = "disabled";
				};
			};

			audio-controller@61000 {
				compatible = "amlogic,sm1-pdm", "amlogic,axg-pdm";
				reg = <0x0 0x61000 0x0 0x34>;
				#sound-dai-cells = <0x0>;
				sound-name-prefix = "PDM";
				clocks = <0x1c 0x1e 0x1c 0x39 0x1c 0x3a>;
				clock-names = "pclk", "dclk", "sysclk";
				status = "disabled";
			};
		};

		bus@ff800000 {
			compatible = "simple-bus";
			reg = <0x0 0xff800000 0x0 0x100000>;
			#address-cells = <0x2>;
			#size-cells = <0x2>;
			ranges = <0x0 0x0 0x0 0xff800000 0x0 0x100000>;

			sys-ctrl@0 {
				compatible = "amlogic,meson-gx-ao-sysctrl", "simple-mfd", "syscon";
				reg = <0x0 0x0 0x0 0x100>;
				#address-cells = <0x2>;
				#size-cells = <0x2>;
				ranges = <0x0 0x0 0x0 0x0 0x0 0x100>;
				phandle = <0x19>;

				clock-controller {
					compatible = "amlogic,meson-g12a-aoclkc";
					#clock-cells = <0x1>;
					#reset-cells = <0x1>;
					clocks = <0x16 0x2 0xa>;
					clock-names = "xtal", "mpeg-clk";
					phandle = <0x1f>;
				};

				pinctrl@14 {
					compatible = "amlogic,meson-g12a-aobus-pinctrl";
					#address-cells = <0x2>;
					#size-cells = <0x2>;
					ranges;
					phandle = <0x1e>;

					bank@14 {
						reg = <0x0 0x14 0x0 0x8 0x0 0x1c 0x0 0x8 0x0 0x24 0x0 0x14>;
						reg-names = "mux", "ds", "gpio";
						gpio-controller;
						#gpio-cells = <0x2>;
						gpio-ranges = <0x1e 0x0 0x0 0xf>;
						phandle = <0x41>;
					};

					i2c_ao_sck_pins {
						phandle = <0x25>;

						mux {
							groups = "i2c_ao_sck";
							function = "i2c_ao";
							bias-disable;
							drive-strength-microamp = <0xbb8>;
						};
					};

					i2c_ao_sda {
						phandle = <0x26>;

						mux {
							groups = "i2c_ao_sda";
							function = "i2c_ao";
							bias-disable;
							drive-strength-microamp = <0xbb8>;
						};
					};

					i2c_ao_sck_e {

						mux {
							groups = "i2c_ao_sck_e";
							function = "i2c_ao";
							bias-disable;
							drive-strength-microamp = <0xbb8>;
						};
					};

					i2c_ao_sda_e {

						mux {
							groups = "i2c_ao_sda_e";
							function = "i2c_ao";
							bias-disable;
							drive-strength-microamp = <0xbb8>;
						};
					};

					mclk0-ao {

						mux {
							groups = "mclk0_ao";
							function = "mclk0_ao";
							bias-disable;
							drive-strength-microamp = <0xbb8>;
						};
					};

					tdm-ao-b-din0 {

						mux {
							groups = "tdm_ao_b_din0";
							function = "tdm_ao_b";
							bias-disable;
						};
					};

					spdif-ao-out {

						mux {
							groups = "spdif_ao_out";
							function = "spdif_ao_out";
							drive-strength-microamp = <0x1f4>;
							bias-disable;
						};
					};

					tdm-ao-b-din1 {

						mux {
							groups = "tdm_ao_b_din1";
							function = "tdm_ao_b";
							bias-disable;
						};
					};

					tdm-ao-b-din2 {

						mux {
							groups = "tdm_ao_b_din2";
							function = "tdm_ao_b";
							bias-disable;
						};
					};

					tdm-ao-b-dout0 {

						mux {
							groups = "tdm_ao_b_dout0";
							function = "tdm_ao_b";
							bias-disable;
							drive-strength-microamp = <0xbb8>;
						};
					};

					tdm-ao-b-dout1 {

						mux {
							groups = "tdm_ao_b_dout1";
							function = "tdm_ao_b";
							bias-disable;
							drive-strength-microamp = <0xbb8>;
						};
					};

					tdm-ao-b-dout2 {

						mux {
							groups = "tdm_ao_b_dout2";
							function = "tdm_ao_b";
							bias-disable;
							drive-strength-microamp = <0xbb8>;
						};
					};

					tdm-ao-b-fs {

						mux {
							groups = "tdm_ao_b_fs";
							function = "tdm_ao_b";
							bias-disable;
							drive-strength-microamp = <0xbb8>;
						};
					};

					tdm-ao-b-sclk {

						mux {
							groups = "tdm_ao_b_sclk";
							function = "tdm_ao_b";
							bias-disable;
							drive-strength-microamp = <0xbb8>;
						};
					};

					tdm-ao-b-slv-fs {

						mux {
							groups = "tdm_ao_b_slv_fs";
							function = "tdm_ao_b";
							bias-disable;
						};
					};

					tdm-ao-b-slv-sclk {

						mux {
							groups = "tdm_ao_b_slv_sclk";
							function = "tdm_ao_b";
							bias-disable;
						};
					};

					uart-a-ao {
						phandle = <0x24>;

						mux {
							groups = "uart_ao_a_tx", "uart_ao_a_rx";
							function = "uart_ao_a";
							bias-disable;
						};
					};

					uart-ao-a-cts-rts {

						mux {
							groups = "uart_ao_a_cts", "uart_ao_a_rts";
							function = "uart_ao_a";
							bias-disable;
						};
					};

					pwm-a-e {

						mux {
							groups = "pwm_a_e";
							function = "pwm_a_e";
							bias-disable;
						};
					};

					pwm-ao-a {

						mux {
							groups = "pwm_ao_a";
							function = "pwm_ao_a";
							bias-disable;
						};
					};

					pwm-ao-b {

						mux {
							groups = "pwm_ao_b";
							function = "pwm_ao_b";
							bias-disable;
						};
					};

					pwm-ao-c-4 {

						mux {
							groups = "pwm_ao_c_4";
							function = "pwm_ao_c";
							bias-disable;
						};
					};

					pwm-ao-c-6 {

						mux {
							groups = "pwm_ao_c_6";
							function = "pwm_ao_c";
							bias-disable;
						};
					};

					pwm-ao-d-5 {

						mux {
							groups = "pwm_ao_d_5";
							function = "pwm_ao_d";
							bias-disable;
						};
					};

					pwm-ao-d-10 {

						mux {
							groups = "pwm_ao_d_10";
							function = "pwm_ao_d";
							bias-disable;
						};
					};

					pwm-ao-d-e {
						phandle = <0x23>;

						mux {
							groups = "pwm_ao_d_e";
							function = "pwm_ao_d";
						};
					};

					remote-input-ao {
						phandle = <0x28>;

						mux {
							groups = "remote_ao_input";
							function = "remote_ao_input";
							bias-disable;
						};
					};
				};
			};

			rtc@0a8 {
				compatible = "amlogic,meson-vrtc";
				reg = <0x0 0xa8 0x0 0x4>;
			};

			cec@100 {
				compatible = "amlogic,meson-gx-ao-cec";
				reg = <0x0 0x100 0x0 0x14>;
				interrupts = <0x0 0xc7 0x1>;
				clocks = <0x1f 0x1b>;
				clock-names = "core";
				status = "disabled";
				pinctrl-0 = <0x20>;
				pinctrl-names = "default";
				hdmi-phandle = <0x21>;
			};

			ao-secure@140 {
				compatible = "amlogic,meson-gx-ao-secure", "syscon";
				reg = <0x0 0x140 0x0 0x140>;
				amlogic,has-chip-id;
				phandle = <0x15>;
			};

			cec@280 {
				compatible = "amlogic,meson-sm1-ao-cec";
				reg = <0x0 0x280 0x0 0x1c>;
				interrupts = <0x0 0xcb 0x1>;
				clocks = <0x1f 0x13>;
				clock-names = "oscin";
				status = "okay";
				pinctrl-0 = <0x22>;
				pinctrl-names = "default";
				hdmi-phandle = <0x21>;
			};

			pwm@2000 {
				compatible = "amlogic,meson-g12a-ao-pwm-cd";
				reg = <0x0 0x2000 0x0 0x20>;
				#pwm-cells = <0x3>;
				status = "okay";
				pinctrl-0 = <0x23>;
				pinctrl-names = "default";
				clocks = <0x16>;
				clock-names = "clkin1";
				phandle = <0x4b>;
			};

			serial@3000 {
				compatible = "amlogic,meson-gx-uart", "amlogic,meson-ao-uart";
				reg = <0x0 0x3000 0x0 0x18>;
				interrupts = <0x0 0xc1 0x1>;
				clocks = <0x16 0x1f 0x4 0x16>;
				clock-names = "xtal", "pclk", "baud";
				status = "okay";
				pinctrl-0 = <0x24>;
				pinctrl-names = "default";
			};

			serial@4000 {
				compatible = "amlogic,meson-gx-uart", "amlogic,meson-ao-uart";
				reg = <0x0 0x4000 0x0 0x18>;
				interrupts = <0x0 0xc5 0x1>;
				clocks = <0x16 0x1f 0x6 0x16>;
				clock-names = "xtal", "pclk", "baud";
				status = "disabled";
			};

			i2c@5000 {
				compatible = "amlogic,meson-axg-i2c";
				status = "okay";
				reg = <0x0 0x5000 0x0 0x20>;
				interrupts = <0x0 0xc3 0x1>;
				#address-cells = <0x1>;
				#size-cells = <0x0>;
				clocks = <0x2 0x18>;
				pinctrl-0 = <0x25 0x26>;
				pinctrl-names = "default";

				gpio-controller@20 {
					compatible = "ti,tca6408";
					reg = <0x20>;
					vcc-supply = <0x27>;
					gpio-controller;
					#gpio-cells = <0x2>;
					phandle = <0x42>;
				};

				rtc@51 {
					compatible = "haoyu,hym8563";
					reg = <0x51>;
					#clock-cells = <0x0>;
				};
			};

			pwm@7000 {
				compatible = "amlogic,meson-g12a-ao-pwm-ab";
				reg = <0x0 0x7000 0x0 0x20>;
				#pwm-cells = <0x3>;
				status = "disabled";
			};

			ir@8000 {
				compatible = "amlogic,meson-gxbb-ir";
				reg = <0x0 0x8000 0x0 0x20>;
				interrupts = <0x0 0xc4 0x1>;
				status = "okay";
				pinctrl-0 = <0x28>;
				pinctrl-names = "default";
				linux,rc-map-name = "rc-khadas";
			};

			adc@9000 {
				compatible = "amlogic,meson-g12a-saradc", "amlogic,meson-saradc";
				reg = <0x0 0x9000 0x0 0x48>;
				#io-channel-cells = <0x1>;
				interrupts = <0x0 0xc8 0x1>;
				clocks = <0x16 0x1f 0x8 0x1f 0x12 0x1f 0x10>;
				clock-names = "clkin", "core", "adc_clk", "adc_sel";
				status = "okay";
				vref-supply = <0x29>;
				phandle = <0x40>;
			};
		};

		video-decoder@ff620000 {
			compatible = "amlogic,sm1-vdec";
			reg = <0x0 0xff620000 0x0 0x10000 0x0 0xffd0e180 0x0 0xe4>;
			reg-names = "dos", "esparser";
			interrupts = <0x0 0x2c 0x1 0x0 0x20 0x1>;
			interrupt-names = "vdec", "esparser";
			amlogic,ao-sysctrl = <0x19>;
			amlogic,canvas = <0x2a>;
			clocks = <0x2 0x2e 0x2 0x10 0x2 0xcc 0x2 0xcf 0x2 0xd2>;
			clock-names = "dos_parser", "dos", "vdec_1", "vdec_hevc", "vdec_hevcf";
			resets = <0x5 0x28>;
			reset-names = "esparser";
		};

		vpu@ff900000 {
			compatible = "amlogic,meson-g12a-vpu";
			reg = <0x0 0xff900000 0x0 0x100000 0x0 0xff63c000 0x0 0x1000>;
			reg-names = "vpu", "hhi";
			interrupts = <0x0 0x3 0x1>;
			#address-cells = <0x1>;
			#size-cells = <0x0>;
			amlogic,canvas = <0x2a>;
			power-domains = <0x3 0x0>;

			port@0 {
				reg = <0x0>;
			};

			port@1 {
				reg = <0x1>;

				endpoint {
					remote-endpoint = <0x2b>;
					phandle = <0x12>;
				};
			};
		};

		interrupt-controller@ffc01000 {
			compatible = "arm,gic-400";
			reg = <0x0 0xffc01000 0x0 0x1000 0x0 0xffc02000 0x0 0x2000 0x0 0xffc04000 0x0 0x2000 0x0 0xffc06000 0x0 0x2000>;
			interrupt-controller;
			interrupts = <0x1 0x9 0xff04>;
			#interrupt-cells = <0x3>;
			#address-cells = <0x0>;
			phandle = <0x1>;
		};

		bus@ffd00000 {
			compatible = "simple-bus";
			reg = <0x0 0xffd00000 0x0 0x100000>;
			#address-cells = <0x2>;
			#size-cells = <0x2>;
			ranges = <0x0 0x0 0x0 0xffd00000 0x0 0x100000>;

			reset-controller@1004 {
				compatible = "amlogic,meson-axg-reset";
				reg = <0x0 0x1004 0x0 0x9c>;
				#reset-cells = <0x1>;
				phandle = <0x5>;
			};

			interrupt-controller@f080 {
				compatible = "amlogic,meson-sm1-gpio-intc", "amlogic,meson-gpio-intc";
				reg = <0x0 0xf080 0x0 0x10>;
				interrupt-controller;
				#interrupt-cells = <0x2>;
				amlogic,channel-interrupts = <0x40 0x41 0x42 0x43 0x44 0x45 0x46 0x47>;
				phandle = <0x1b>;
			};

			pwm@19000 {
				compatible = "amlogic,meson-g12a-ee-pwm";
				reg = <0x0 0x19000 0x0 0x20>;
				#pwm-cells = <0x3>;
				status = "okay";
				pinctrl-0 = <0x2c>;
				pinctrl-names = "default";
				phandle = <0x4a>;
			};

			pwm@1a000 {
				compatible = "amlogic,meson-g12a-ee-pwm";
				reg = <0x0 0x1a000 0x0 0x20>;
				#pwm-cells = <0x3>;
				status = "disabled";
			};

			pwm@1b000 {
				compatible = "amlogic,meson-g12a-ee-pwm";
				reg = <0x0 0x1b000 0x0 0x20>;
				#pwm-cells = <0x3>;
				status = "disabled";
			};

			i2c@1c000 {
				compatible = "amlogic,meson-axg-i2c";
				status = "disabled";
				reg = <0x0 0x1c000 0x0 0x20>;
				interrupts = <0x0 0x27 0x1>;
				#address-cells = <0x1>;
				#size-cells = <0x0>;
				clocks = <0x2 0x18>;
			};

			i2c@1d000 {
				compatible = "amlogic,meson-axg-i2c";
				status = "disabled";
				reg = <0x0 0x1d000 0x0 0x20>;
				interrupts = <0x0 0xd7 0x1>;
				#address-cells = <0x1>;
				#size-cells = <0x0>;
				clocks = <0x2 0x18>;
			};

			i2c@1e000 {
				compatible = "amlogic,meson-axg-i2c";
				status = "disabled";
				reg = <0x0 0x1e000 0x0 0x20>;
				interrupts = <0x0 0xd6 0x1>;
				#address-cells = <0x1>;
				#size-cells = <0x0>;
				clocks = <0x2 0x18>;
			};

			i2c@1f000 {
				compatible = "amlogic,meson-axg-i2c";
				status = "disabled";
				reg = <0x0 0x1f000 0x0 0x20>;
				interrupts = <0x0 0x15 0x1>;
				#address-cells = <0x1>;
				#size-cells = <0x0>;
				clocks = <0x2 0x18>;
			};

			clock-measure@18000 {
				compatible = "amlogic,meson-sm1-clk-measure";
				reg = <0x0 0x18000 0x0 0x10>;
			};

			serial@22000 {
				compatible = "amlogic,meson-gx-uart";
				reg = <0x0 0x22000 0x0 0x18>;
				interrupts = <0x0 0x5d 0x1>;
				clocks = <0x16 0x2 0x39 0x16>;
				clock-names = "xtal", "pclk", "baud";
				status = "disabled";
			};

			serial@23000 {
				compatible = "amlogic,meson-gx-uart";
				reg = <0x0 0x23000 0x0 0x18>;
				interrupts = <0x0 0x4b 0x1>;
				clocks = <0x16 0x2 0x2a 0x16>;
				clock-names = "xtal", "pclk", "baud";
				status = "disabled";
			};

			serial@24000 {
				compatible = "amlogic,meson-gx-uart";
				reg = <0x0 0x24000 0x0 0x18>;
				interrupts = <0x0 0x1a 0x1>;
				clocks = <0x16 0x2 0x1c 0x16>;
				clock-names = "xtal", "pclk", "baud";
				status = "okay";
				pinctrl-0 = <0x2d 0x2e>;
				pinctrl-names = "default";
				uart-has-rtscts;

				bluetooth {
					compatible = "brcm,bcm43438-bt";
					shutdown-gpios = <0x7 0x52 0x0>;
					max-speed = <0x1e8480>;
					clocks = <0x2f>;
					clock-names = "lpo";
				};
			};
		};

		sd@ffe03000 {
			compatible = "amlogic,meson-axg-mmc";
			reg = <0x0 0xffe03000 0x0 0x800>;
			interrupts = <0x0 0xbd 0x1>;
			status = "okay";
			clocks = <0x2 0x21 0x2 0x3c 0x2 0x2>;
			clock-names = "core", "clkin0", "clkin1";
			resets = <0x5 0x2c>;
			pinctrl-0 = <0x30>;
			pinctrl-1 = <0x31>;
			pinctrl-names = "default", "clk-gate";
			#address-cells = <0x1>;
			#size-cells = <0x0>;
			bus-width = <0x4>;
			cap-sd-highspeed;
			max-frequency = <0x5f5e100>;
			non-removable;
			disable-wp;
			keep-power-in-suspend;
			mmc-pwrseq = <0x32>;
			vmmc-supply = <0x33>;
			vqmmc-supply = <0x29>;

			wifi@1 {
				reg = <0x1>;
				compatible = "brcm,bcm4329-fmac";
			};
		};

		sd@ffe05000 {
			compatible = "amlogic,meson-axg-mmc";
			reg = <0x0 0xffe05000 0x0 0x800>;
			interrupts = <0x0 0xbe 0x1>;
			status = "okay";
			clocks = <0x2 0x22 0x2 0x3d 0x2 0x2>;
			clock-names = "core", "clkin0", "clkin1";
			resets = <0x5 0x2d>;
			pinctrl-0 = <0x34>;
			pinctrl-1 = <0x35>;
			pinctrl-names = "default", "clk-gate";
			bus-width = <0x4>;
			cap-sd-highspeed;
			max-frequency = <0x2faf080>;
			disable-wp;
			cd-gpios = <0x7 0x2f 0x1>;
			vmmc-supply = <0x33>;
			vqmmc-supply = <0x33>;
		};

		mmc@ffe07000 {
			compatible = "amlogic,meson-axg-mmc";
			reg = <0x0 0xffe07000 0x0 0x800>;
			interrupts = <0x0 0xbf 0x1>;
			status = "okay";
			clocks = <0x2 0x23 0x2 0x3e 0x2 0x2>;
			clock-names = "core", "clkin0", "clkin1";
			resets = <0x5 0x2e>;
			pinctrl-0 = <0x36 0x37>;
			pinctrl-1 = <0x38>;
			pinctrl-names = "default", "clk-gate";
			bus-width = <0x8>;
			cap-mmc-highspeed;
			mmc-ddr-1_8v;
			mmc-hs200-1_8v;
			max-frequency = <0xbebc200>;
			disable-wp;
			mmc-pwrseq = <0x39>;
			vmmc-supply = <0x27>;
			vqmmc-supply = <0x3a>;
		};

		usb@ffe09000 {
			status = "okay";
			compatible = "amlogic,meson-g12a-usb-ctrl";
			reg = <0x0 0xffe09000 0x0 0xa0>;
			interrupts = <0x0 0x10 0x4>;
			#address-cells = <0x2>;
			#size-cells = <0x2>;
			ranges;
			clocks = <0x2 0x2f>;
			resets = <0x5 0x22>;
			dr_mode = "host";
			phys = <0x3b 0x3c 0x6 0x4>;
			phy-names = "usb2-phy0", "usb2-phy1", "usb3-phy0";
			power-domains = <0x3 0x2>;

			usb@ff400000 {
				compatible = "amlogic,meson-g12a-usb", "snps,dwc2";
				reg = <0x0 0xff400000 0x0 0x40000>;
				interrupts = <0x0 0x1f 0x4>;
				clocks = <0x2 0x37>;
				clock-names = "ddr";
				phys = <0x3c>;
				phy-names = "usb2-phy";
				dr_mode = "peripheral";
				g-rx-fifo-size = <0xc0>;
				g-np-tx-fifo-size = <0x80>;
				g-tx-fifo-size = <0x80 0x80 0x10 0x10 0x10>;
			};

			usb@ff500000 {
				compatible = "snps,dwc3";
				reg = <0x0 0xff500000 0x0 0x100000>;
				interrupts = <0x0 0x1e 0x4>;
				dr_mode = "host";
				snps,dis_u2_susphy_quirk;
				snps,quirk-frame-length-adjustment;
				snps,parkmode-disable-ss-quirk;
			};
		};

		gpu@ffe40000 {
			compatible = "amlogic,meson-g12a-mali", "arm,mali-bifrost";
			reg = <0x0 0xffe40000 0x0 0x40000>;
			interrupt-parent = <0x1>;
			interrupts = <0x0 0xa2 0x4 0x0 0xa1 0x4 0x0 0xa0 0x4>;
			interrupt-names = "job", "mmu", "gpu";
			clocks = <0x2 0xaf>;
			resets = <0x5 0x14 0x5 0x4e>;
			assigned-clocks = <0x2 0xa9 0x2 0xab 0x2 0xaf>;
			assigned-clock-parents = <0x2 0x63 0x0 0x2 0xab>;
			assigned-clock-rates = <0x0 0x2faf0800 0x0>;
			#cooling-cells = <0x2>;
			phandle = <0xb>;
		};
	};

	timer {
		compatible = "arm,armv8-timer";
		interrupts = <0x1 0xd 0xff08 0x1 0xe 0xff08 0x1 0xb 0xff08 0x1 0xa 0xff08>;
		arm,no-tick-in-suspend;
	};

	xtal-clk {
		compatible = "fixed-clock";
		clock-frequency = <0x16e3600>;
		clock-output-names = "xtal";
		#clock-cells = <0x0>;
		phandle = <0x16>;
	};

	audio-controller-0 {
		compatible = "amlogic,axg-tdm-iface";
		#sound-dai-cells = <0x0>;
		sound-name-prefix = "TDM_A";
		clocks = <0x1c 0x31 0x1c 0x4f 0x1c 0x56>;
		clock-names = "mclk", "sclk", "lrclk";
		status = "disabled";
	};

	audio-controller-1 {
		compatible = "amlogic,axg-tdm-iface";
		#sound-dai-cells = <0x0>;
		sound-name-prefix = "TDM_B";
		clocks = <0x1c 0x32 0x1c 0x50 0x1c 0x57>;
		clock-names = "mclk", "sclk", "lrclk";
		status = "okay";
		phandle = <0x47>;
	};

	audio-controller-2 {
		compatible = "amlogic,axg-tdm-iface";
		#sound-dai-cells = <0x0>;
		sound-name-prefix = "TDM_C";
		clocks = <0x1c 0x33 0x1c 0x51 0x1c 0x58>;
		clock-names = "mclk", "sclk", "lrclk";
		status = "disabled";
	};

	cpus {
		#address-cells = <0x2>;
		#size-cells = <0x0>;

		cpu@0 {
			device_type = "cpu";
			compatible = "arm,cortex-a55";
			reg = <0x0 0x0>;
			enable-method = "psci";
			next-level-cache = <0x3d>;
			cpu-supply = <0x3e>;
			operating-points-v2 = <0x3f>;
			clocks = <0x2 0xbb>;
			clock-latency = <0xc350>;
		};

		cpu@1 {
			device_type = "cpu";
			compatible = "arm,cortex-a55";
			reg = <0x0 0x1>;
			enable-method = "psci";
			next-level-cache = <0x3d>;
			cpu-supply = <0x3e>;
			operating-points-v2 = <0x3f>;
			clocks = <0x2 0xfd>;
			clock-latency = <0xc350>;
		};

		cpu@2 {
			device_type = "cpu";
			compatible = "arm,cortex-a55";
			reg = <0x0 0x2>;
			enable-method = "psci";
			next-level-cache = <0x3d>;
			cpu-supply = <0x3e>;
			operating-points-v2 = <0x3f>;
			clocks = <0x2 0xfe>;
			clock-latency = <0xc350>;
		};

		cpu@3 {
			device_type = "cpu";
			compatible = "arm,cortex-a55";
			reg = <0x0 0x3>;
			enable-method = "psci";
			next-level-cache = <0x3d>;
			cpu-supply = <0x3e>;
			operating-points-v2 = <0x3f>;
			clocks = <0x2 0xff>;
			clock-latency = <0xc350>;
		};

		l2-cache0 {
			compatible = "cache";
			phandle = <0x3d>;
		};
	};

	opp-table {
		compatible = "operating-points-v2";
		opp-shared;
		phandle = <0x3f>;

		opp-100000000 {
			opp-hz = <0x0 0x5f5e100>;
			opp-microvolt = <0xb2390>;
		};

		opp-250000000 {
			opp-hz = <0x0 0xee6b280>;
			opp-microvolt = <0xb2390>;
		};

		opp-500000000 {
			opp-hz = <0x0 0x1dcd6500>;
			opp-microvolt = <0xb2390>;
		};

		opp-667000000 {
			opp-hz = <0x0 0x27bc86aa>;
			opp-microvolt = <0xb71b0>;
		};

		opp-1000000000 {
			opp-hz = <0x0 0x3b9aca00>;
			opp-microvolt = <0xbbfd0>;
		};

		opp-1200000000 {
			opp-hz = <0x0 0x47868c00>;
			opp-microvolt = <0xbe6e0>;
		};

		opp-1404000000 {
			opp-hz = <0x0 0x53af5700>;
			opp-microvolt = <0xc0df0>;
		};

		opp-1512000000 {
			opp-hz = <0x0 0x59682f00>;
			opp-microvolt = <0xc3500>;
		};

		opp-1608000000 {
			opp-hz = <0x0 0x5fd82200>;
			opp-microvolt = <0xc5c10>;
		};

		opp-1704000000 {
			opp-hz = <0x0 0x6590fa00>;
			opp-microvolt = <0xcf850>;
		};

		opp-1800000000 {
			opp-hz = <0x0 0x6b49d200>;
			opp-microvolt = <0xdbba0>;
		};

		opp-1908000000 {
			opp-hz = <0x0 0x71b9c500>;
			opp-microvolt = <0xe7ef0>;
		};
	};

	aliases {
		serial0 = "/soc/bus@ff800000/serial@3000";
		ethernet0 = "/soc/ethernet@ff3f0000";
	};

	memory@0 {
		device_type = "memory";
		reg = <0x0 0x0 0x0 0x80000000>;
	};

	adc-keys {
		compatible = "adc-keys";
		io-channels = <0x40 0x2>;
		io-channel-names = "buttons";
		keyup-threshold-microvolt = <0x1a17b0>;

		button-function {
			label = "Function";
			linux,code = <0x1d0>;
			press-threshold-microvolt = <0x2710>;
		};
	};

	leds {
		compatible = "gpio-leds";

		white {
			label = "vim3:white:sys";
			gpios = <0x41 0x4 0x1>;
		};

		red {
			label = "vim3:red";
			gpios = <0x42 0x5 0x1>;
		};
	};

	emmc-pwrseq {
		compatible = "mmc-pwrseq-emmc";
		reset-gpios = <0x7 0x25 0x1>;
		phandle = <0x39>;
	};

	gpio-keys-polled {
		compatible = "gpio-keys-polled";
		poll-interval = <0x64>;

		power-button {
			label = "power";
			linux,code = <0x74>;
			gpios = <0x41 0x7 0x1>;
		};
	};

	sdio-pwrseq {
		compatible = "mmc-pwrseq-simple";
		reset-gpios = <0x7 0x47 0x1>;
		clocks = <0x2f>;
		clock-names = "ext_clock";
		phandle = <0x32>;
	};

	sound {
		compatible = "amlogic,axg-sound-card";
		model = "AMLG12";
		audio-aux-devs = <0x43>;
		audio-routing = "TDMOUT_B IN 0", "FRDDR_A OUT 1", "TDMOUT_B IN 1", "FRDDR_B OUT 1", "TDMOUT_B IN 2", "FRDDR_C OUT 1", "TDM_B Playback", "TDMOUT_B OUT";
		assigned-clocks = <0x2 0xd 0x2 0xb 0x2 0xc>;
		assigned-clock-parents = <0x0 0x0 0x0>;
		assigned-clock-rates = <0x11940000 0x10266000 0x17700000>;
		status = "okay";

		dai-link-0 {
			sound-dai = <0x44>;
		};

		dai-link-1 {
			sound-dai = <0x45>;
		};

		dai-link-2 {
			sound-dai = <0x46>;
		};

		dai-link-3 {
			sound-dai = <0x47>;
			dai-format = "i2s";
			dai-tdm-slot-tx-mask-0 = <0x1 0x1>;
			dai-tdm-slot-tx-mask-1 = <0x1 0x1>;
			dai-tdm-slot-tx-mask-2 = <0x1 0x1>;
			dai-tdm-slot-tx-mask-3 = <0x1 0x1>;
			mclk-fs = <0x100>;

			codec {
				sound-dai = <0x48 0x1>;
			};
		};

		dai-link-4 {
			sound-dai = <0x48 0x3>;

			codec {
				sound-dai = <0x21>;
			};
		};
	};

	regulator-dc_in {
		compatible = "regulator-fixed";
		regulator-name = "DC_IN";
		regulator-min-microvolt = <0x4c4b40>;
		regulator-max-microvolt = <0x4c4b40>;
		regulator-always-on;
		phandle = <0x17>;
	};

	regulator-vcc_5v {
		compatible = "regulator-fixed";
		regulator-name = "VCC_5V";
		regulator-min-microvolt = <0x4c4b40>;
		regulator-max-microvolt = <0x4c4b40>;
		vin-supply = <0x17>;
		gpio = <0x7 0x18 0x6>;
		enable-active-high;
		phandle = <0x11>;
	};

	regulator-vcc_1v8 {
		compatible = "regulator-fixed";
		regulator-name = "VCC_1V8";
		regulator-min-microvolt = <0x1b7740>;
		regulator-max-microvolt = <0x1b7740>;
		vin-supply = <0x27>;
		regulator-always-on;
	};

	regulator-vcc_3v3 {
		compatible = "regulator-fixed";
		regulator-name = "VCC_3V3";
		regulator-min-microvolt = <0x325aa0>;
		regulator-max-microvolt = <0x325aa0>;
		vin-supply = <0x33>;
		regulator-always-on;
		phandle = <0x27>;
	};

	regulator-vddao_1v8 {
		compatible = "regulator-fixed";
		regulator-name = "VDDIO_AO1V8";
		regulator-min-microvolt = <0x1b7740>;
		regulator-max-microvolt = <0x1b7740>;
		vin-supply = <0x33>;
		regulator-always-on;
		phandle = <0x29>;
	};

	regulator-emmc_1v8 {
		compatible = "regulator-fixed";
		regulator-name = "EMMC_AO1V8";
		regulator-min-microvolt = <0x1b7740>;
		regulator-max-microvolt = <0x1b7740>;
		vin-supply = <0x27>;
		regulator-always-on;
		phandle = <0x3a>;
	};

	regulator-vsys_3v3 {
		compatible = "regulator-fixed";
		regulator-name = "VSYS_3V3";
		regulator-min-microvolt = <0x325aa0>;
		regulator-max-microvolt = <0x325aa0>;
		vin-supply = <0x17>;
		regulator-always-on;
		phandle = <0x33>;
	};

	regulator-usb_pwr {
		compatible = "regulator-fixed";
		regulator-name = "USB_PWR";
		regulator-min-microvolt = <0x4c4b40>;
		regulator-max-microvolt = <0x4c4b40>;
		vin-supply = <0x11>;
		gpio = <0x7 0x37 0x0>;
		enable-active-high;
		phandle = <0x18>;
	};

	hdmi-connector {
		compatible = "hdmi-connector";
		type = [61 00];

		port {

			endpoint {
				remote-endpoint = <0x49>;
				phandle = <0x13>;
			};
		};
	};

	wifi32k {
		compatible = "pwm-clock";
		#clock-cells = <0x0>;
		clock-frequency = <0x8000>;
		pwms = <0x4a 0x0 0x7736 0x0>;
		phandle = <0x2f>;
	};

	regulator-vddcpu {
		compatible = "pwm-regulator";
		regulator-name = "VDDCPU";
		regulator-min-microvolt = <0xa8750>;
		regulator-max-microvolt = <0x100590>;
		vin-supply = <0x33>;
		pwms = <0x4b 0x1 0x4e2 0x0>;
		pwm-dutycycle-range = <0x64 0x0>;
		regulator-boot-on;
		regulator-always-on;
		phandle = <0x3e>;
	};
};
